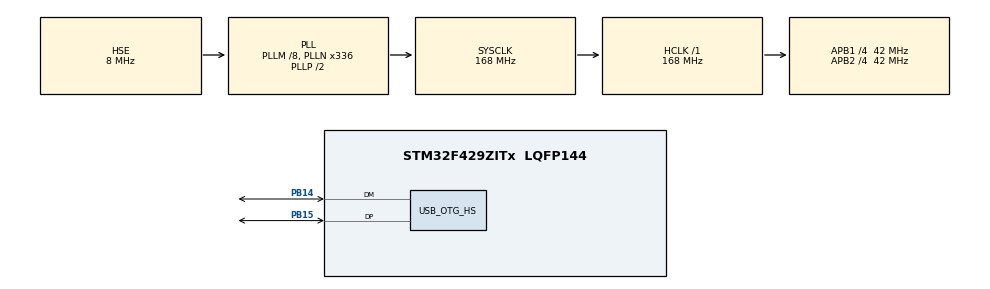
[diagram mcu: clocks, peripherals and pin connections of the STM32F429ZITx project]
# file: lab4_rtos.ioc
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FREERTOS.Tasks01=defaultTask,24,128,StartDefaultTask,Default,NULL,Dynamic,NULL,NULL;Task01,24,256,StartTask01,Default,NULL,Dynamic,NULL,NULL;Task02,24,128,StartTask02,Default,NULL,Dynamic,NULL,NULL
Mcu.Family=STM32F4
Mcu.Name=STM32F429ZITx
Mcu.Package=LQFP144
NVIC.OTG_HS_IRQn=true\:5\:0\:false\:false\:true\:true\:true\:true\:true
NVIC.PriorityGroup=NVIC_PRIORITYGROUP_4
NVIC.TIM6_DAC_IRQn=true\:15\:0\:false\:false\:true\:false\:false\:true\:true
NVIC.TimeBase=TIM6_DAC_IRQn
NVIC.TimeBaseIP=TIM6
PA13.Mode=Serial_Wire
PA13.Signal=SYS_JTMS-SWDIO
PA14.Mode=Serial_Wire
PA14.Signal=SYS_JTCK-SWCLK
PB14.Mode=Device_Only_FS
PB14.Signal=USB_OTG_HS_DM
PB15.Mode=Device_Only_FS
PB15.Signal=USB_OTG_HS_DP
PH0/OSC_IN.Mode=HSE-External-Oscillator
PH0/OSC_IN.Signal=RCC_OSC_IN
PH1/OSC_OUT.Mode=HSE-External-Oscillator
PH1/OSC_OUT.Signal=RCC_OSC_OUT
ProjectManager.HeapSize=0x2000
ProjectManager.StackSize=0x400
ProjectManager.TargetToolchain=STM32CubeIDE
RCC.48MHZClocksFreq_Value=48000000
RCC.AHBFreq_Value=168000000
RCC.APB1CLKDivider=RCC_HCLK_DIV4
RCC.APB1Freq_Value=42000000
RCC.APB1TimFreq_Value=84000000
RCC.APB2CLKDivider=RCC_HCLK_DIV4
RCC.APB2Freq_Value=42000000
RCC.APB2TimFreq_Value=84000000
RCC.CortexFreq_Value=168000000
RCC.HCLKFreq_Value=168000000
RCC.HSE_VALUE=8000000
RCC.HSI_VALUE=16000000
RCC.LSE_VALUE=32768
RCC.PLLM=8
RCC.PLLN=336
RCC.PLLQ=7
RCC.SYSCLKFreq_VALUE=168000000
RCC.SYSCLKSource=RCC_SYSCLKSOURCE_PLLCLK
RCC.VCOOutputFreq_Value=336000000
USB_DEVICE.CLASS_NAME_HS=CDC
USB_DEVICE.VirtualMode-CDC_HS=Cdc
USB_DEVICE.VirtualModeHS=Cdc_HS
USB_OTG_HS.VirtualMode-Device_Only_FS=Device_Only_FS
VP_FREERTOS_VS_CMSIS_V2.Mode=CMSIS_V2
VP_SYS_VS_tim6.Mode=TIM6
VP_USB_DEVICE_VS_USB_DEVICE_CDC_HS.Mode=CDC_HS
board=custom

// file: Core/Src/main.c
/* USER CODE BEGIN Header */
/**
  ******************************************************************************
  * @file           : main.c
  * @brief          : Main program body
  ******************************************************************************
  * @attention
  *
  * Copyright (c) 2024 STMicroelectronics.
  * All rights reserved.
  *
  * This software is licensed under terms that can be found in the LICENSE file
  * in the root directory of this software component.
  * If no LICENSE file comes with this software, it is provided AS-IS.
  *
  ******************************************************************************
  */
/* USER CODE END Header */
#include "main.h"
#include "cmsis_os.h"
#include "usb_device.h"

/* USER CODE BEGIN Includes */
#include "usbd_cdc_if.h"
#include "stm32f429i_discovery_lcd.h"
#include "stm32f429i_discovery_sdram.h"
#include "stm32f429i_discovery_gyroscope.h"
/* USER CODE END Includes */

/* USER CODE BEGIN PD */
// Ngưỡng xác định nghiêng
#define THRESHOLD 200
/* USER CODE END PD */

/* Definitions for defaultTask */
osThreadId_t defaultTaskHandle;
const osThreadAttr_t defaultTask_attributes = {
  .name = "defaultTask",
  .stack_size = 128 * 4,
  .priority = (osPriority_t) osPriorityNormal,
};
/* Definitions for Task01 */
osThreadId_t Task01Handle;
const osThreadAttr_t Task01_attributes = {
  .name = "Task01",
  .stack_size = 256 * 4,
  .priority = (osPriority_t) osPriorityNormal,
};
/* Definitions for Task02 */
osThreadId_t Task02Handle;
const osThreadAttr_t Task02_attributes = {
  .name = "Task02",
  .stack_size = 128 * 4,
  .priority = (osPriority_t) osPriorityNormal,
};
/* USER CODE BEGIN PV */
uint8_t buffer[50];
float dataRec[3];
char strX[10], strY[10], strZ[10];
/* USER CODE END PV */

void SystemClock_Config(void);
static void MX_GPIO_Init(void);
void StartDefaultTask(void *argument);
void StartTask01(void *argument);
void StartTask02(void *argument);

/* USER CODE BEGIN 0 */
void DrawArrows(float pitch, float roll) {
    BSP_LCD_Clear(LCD_COLOR_WHITE);

    // Kiểm tra hướng nghiêng
    if (pitch > THRESHOLD) {
        BSP_LCD_DisplayStringAt(120, 50, "▲", CENTER_MODE); // Nghiêng trước
    } else if (pitch < -THRESHOLD) {
    	BSP_LCD_DisplayStringAt(120, 190, "▼", CENTER_MODE); // Nghiêng sau
    }

    if (roll > THRESHOLD) {
    	BSP_LCD_DisplayStringAt(190, 120, "►", CENTER_MODE); // Nghiêng phải
    } else if (roll < -THRESHOLD) {
    	BSP_LCD_DisplayStringAt(50, 120, "◄", CENTER_MODE); // Nghiêng trái
    }

}
/* USER CODE END 0 */

int main(void)
{

  /* MCU Configuration--------------------------------------------------------*/

  /* Reset of all peripherals, Initializes the Flash interface and the Systick. */
  HAL_Init();

  /* Configure the system clock */
  SystemClock_Config();

  /* Initialize all configured peripherals */
  MX_GPIO_Init();
  /* USER CODE BEGIN 2 */
  BSP_LCD_Init();//init LCD
  BSP_SDRAM_Init();
  BSP_GYRO_Init();

  BSP_LCD_LayerDefaultInit(1, SDRAM_DEVICE_ADDR);
  BSP_LCD_SelectLayer(1);
  BSP_LCD_DisplayOn();
  BSP_LCD_Clear(LCD_COLOR_BLUE);
  BSP_LCD_SetBackColor(LCD_COLOR_BLUE);
  BSP_LCD_SetTextColor(LCD_COLOR_WHITE);
  /* USER CODE END 2 */

  /* Init scheduler */
  osKernelInitialize();

  /* Create the thread(s) */
  /* creation of defaultTask */
  defaultTaskHandle = osThreadNew(StartDefaultTask, NULL, &defaultTask_attributes);

  /* creation of Task01 */
  Task01Handle = osThreadNew(StartTask01, NULL, &Task01_attributes);

  /* creation of Task02 */
  Task02Handle = osThreadNew(StartTask02, NULL, &Task02_attributes);

  /* Start scheduler */
  osKernelStart();

  /* We should never get here as control is now taken by the scheduler */

  /* Infinite loop */
  while (1)
  {

  }
}

void SystemClock_Config(void)
{
  RCC_OscInitTypeDef RCC_OscInitStruct = {0};
  RCC_ClkInitTypeDef RCC_ClkInitStruct = {0};

  /** Configure the main internal regulator output voltage
  */
  __HAL_RCC_PWR_CLK_ENABLE();
  __HAL_PWR_VOLTAGESCALING_CONFIG(PWR_REGULATOR_VOLTAGE_SCALE1);

  /** Initializes the RCC Oscillators according to the specified parameters
  * in the RCC_OscInitTypeDef structure.
  */
  RCC_OscInitStruct.OscillatorType = RCC_OSCILLATORTYPE_HSE;
  RCC_OscInitStruct.HSEState = RCC_HSE_ON;
  RCC_OscInitStruct.PLL.PLLState = RCC_PLL_ON;
  RCC_OscInitStruct.PLL.PLLSource = RCC_PLLSOURCE_HSE;
  RCC_OscInitStruct.PLL.PLLM = 8;
  RCC_OscInitStruct.PLL.PLLN = 336;
  RCC_OscInitStruct.PLL.PLLP = RCC_PLLP_DIV2;
  RCC_OscInitStruct.PLL.PLLQ = 7;
  if (HAL_RCC_OscConfig(&RCC_OscInitStruct) != HAL_OK)
  {
    Error_Handler();
  }

  /** Initializes the CPU, AHB and APB buses clocks
  */
  RCC_ClkInitStruct.ClockType = RCC_CLOCKTYPE_HCLK|RCC_CLOCKTYPE_SYSCLK
                              |RCC_CLOCKTYPE_PCLK1|RCC_CLOCKTYPE_PCLK2;
  RCC_ClkInitStruct.SYSCLKSource = RCC_SYSCLKSOURCE_PLLCLK;
  RCC_ClkInitStruct.AHBCLKDivider = RCC_SYSCLK_DIV1;
  RCC_ClkInitStruct.APB1CLKDivider = RCC_HCLK_DIV4;
  RCC_ClkInitStruct.APB2CLKDivider = RCC_HCLK_DIV4;

  if (HAL_RCC_ClockConfig(&RCC_ClkInitStruct, FLASH_LATENCY_5) != HAL_OK)
  {
    Error_Handler();
  }
}

static void MX_GPIO_Init(void)
{

  /* GPIO Ports Clock Enable */
  __HAL_RCC_GPIOH_CLK_ENABLE();
  __HAL_RCC_GPIOB_CLK_ENABLE();
  __HAL_RCC_GPIOA_CLK_ENABLE();

}

void StartDefaultTask(void *argument)
{
  /* init code for USB_DEVICE */
  MX_USB_DEVICE_Init();
  for(;;)
  {
    osDelay(1);
  }
}

void StartTask01(void *argument)
{
  /* USER CODE BEGIN StartTask01 */
  /* Infinite loop */
  for(;;)
  {
	BSP_GYRO_GetXYZ(dataRec);
	sprintf(buffer, "X: %.2f, Y: %.2f, Z: %.2f", dataRec[0], dataRec[1], dataRec[2]);
	CDC_Transmit_HS(buffer, sizeof(buffer));

    osDelay(1000);
  }
  /* USER CODE END StartTask01 */
}

void StartTask02(void *argument)
{
  /* USER CODE BEGIN StartTask02 */
  /* Infinite loop */
  for(;;)
  {
	BSP_GYRO_GetXYZ(dataRec);
	// Hiển thị mũi tên tương ứng với hướng nghiêng
	DrawArrows(dataRec[1], dataRec[0]);

    osDelay(1000);
  }
  /* USER CODE END StartTask02 */
}

void HAL_TIM_PeriodElapsedCallback(TIM_HandleTypeDef *htim)
{
  if (htim->Instance == TIM6) {
    HAL_IncTick();
  }
}

void Error_Handler(void)
{
  __disable_irq();
  while (1)
  {
  }
}
